# STM32F411xE register map
File version: 1.0
Registers are 32-bit, read-write, reset 0x0 unless marked. A register's access mark holds for its fields unless they carry their own. Offsets are from the block's base; [hi:lo] are bit positions; {n}, {i} and the like mark numbered series.

## PWR — Power Control
Base 0x40007000
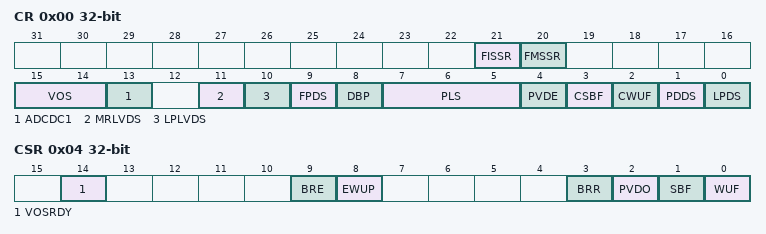
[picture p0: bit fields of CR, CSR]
0x00 CR — PWR power control register
  [21] FISSR — Flash Interface Stop while System Run
  [20] FMSSR — Flash Memory Sleep System Run
  [15:14] VOS — VOS[1:0] bits (Regulator voltage scaling output selection)
    3=SCALE1; 2=SCALE2; 1=SCALE3
  [13] ADCDC1 — Refer to AN4073 on how to use this bit
  [11] MRLVDS — Main Regulator Low Voltage in Deep Sleep mode
  [10] LPLVDS — Low Power Regulator Low Voltage in Deep Sleep mode
  [9] FPDS — Flash power down in Stop mode
  [8] DBP — Disable Backup Domain write protection
  [7:5] PLS — PLS[2:0] bits (PVD Level Selection)
    0=PVDLEVEL_0 (Voltage threshold detected by PVD 2.2 V); 1=PVDLEVEL_1 (Voltage threshold detected by PVD 2.3 V); 2=PVDLEVEL_2 (Voltage threshold detected by PVD 2.4 V); 3=PVDLEVEL_3 (Voltage threshold detected by PVD 2.5 V); 4=PVDLEVEL_4 (Voltage threshold detected by PVD 2.6 V); 5=PVDLEVEL_5 (Voltage threshold detected by PVD 2.7 V); 6=PVDLEVEL_6 (Voltage threshold detected by PVD 2.8 V); 7=PVDLEVEL_7 (Voltage threshold detected by PVD 2.9 V)
  [4] PVDE — Power Voltage Detector Enable
  [3] CSBF — Clear Standby Flag
  [2] CWUF — Clear Wakeup Flag
  [1] PDDS — Power Down Deepsleep
  [0] LPDS — Low-Power Deepsleep
    0=MAIN (Voltage Regulator in main mode during deepsleep mode); 1=LOW_POWER (Voltage Regulator in low-power mode during deepsleep mode)
0x04 CSR — PWR power control/status register
  [14] VOSRDY — Regulator voltage scaling output selection ready
  [9] BRE — Backup regulator enable
  [8] EWUP — Enable WKUP pin
  [3] BRR — Backup regulator ready
  [2] PVDO — PVD Output
  [1] SBF — Standby Flag
  [0] WUF — Wakeup Flag

## SYSCFG — System configuration controller
Base 0x40013800
0x00 MEMRMP — SYSCFG memory remap register
  [1:0] MEM_MODE — SYSCFG_Memory Remap Config
    0=FLASH (Main Flash memory mapped at 0x00000000); 1=SYSTEMFLASH (System Flash memory mapped at 0x00000000); 3=SRAM (SRAM1 mapped at 0x00000000)
0x04 PMC — SYSCFG peripheral mode configuration register
  [16] ADC1DC2 — Refer to AN4073 on how to use this bit
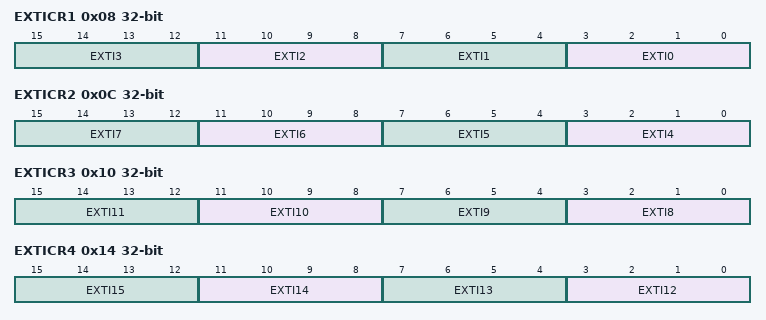
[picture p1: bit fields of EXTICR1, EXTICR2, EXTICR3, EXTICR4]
0x08 EXTICR1 — SYSCFG external interrupt configuration registers
  [4n+3:4n] EXTI{n} (n=0..3) — EXTI {n} configuration
0x0C EXTICR2 — SYSCFG external interrupt configuration registers
  [4n-13:4n-16] EXTI{n} (n=4..7) — EXTI {n} configuration
0x10 EXTICR3 — SYSCFG external interrupt configuration registers
  [4n-29:4n-32] EXTI{n} (n=8..11) — EXTI {n} configuration
0x14 EXTICR4 — SYSCFG external interrupt configuration registers
  [4n-45:4n-48] EXTI{n} (n=12..15) — EXTI {n} configuration
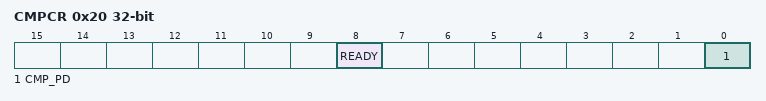
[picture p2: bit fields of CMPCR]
0x20 CMPCR — SYSCFG Compensation cell control register
  [8] READY — Compensation cell power-down
  [0] CMP_PD — Compensation cell ready flag

## EXTI — External Interrupt/Event Controller
Base 0x40013C00
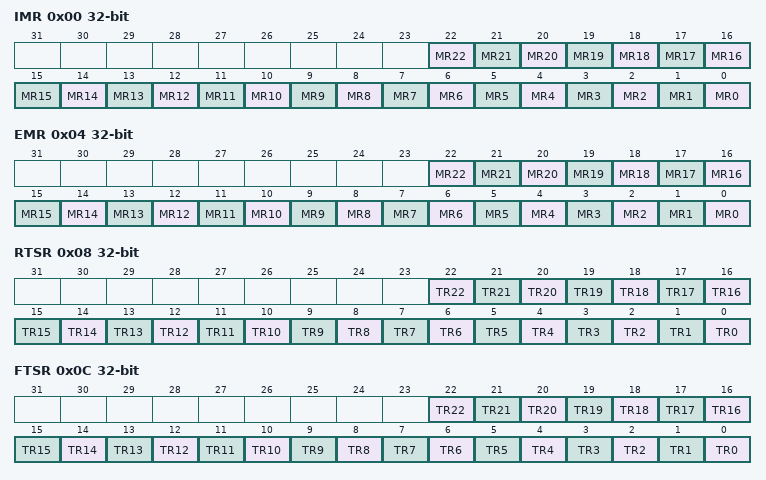
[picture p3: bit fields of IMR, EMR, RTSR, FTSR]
0x00 IMR — EXTI Interrupt mask register
  [n] MR{n} (n=0..22) — Interrupt Mask on line {n}
0x04 EMR — EXTI Event mask register
  [n] MR{n} (n=0..22) — Event Mask on line {n}
0x08 RTSR — EXTI Rising trigger selection register
  [n] TR{n} (n=0..22) — Rising trigger event configuration bit of line {n}
0x0C FTSR — EXTI Falling trigger selection register
  [n] TR{n} (n=0..22) — Falling trigger event configuration bit of line {n}
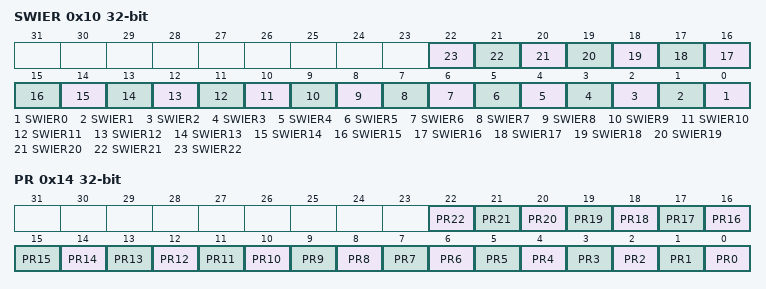
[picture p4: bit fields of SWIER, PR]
0x10 SWIER — EXTI Software interrupt event register
  [n] SWIER{n} (n=0..22) — Software Interrupt on line {n}
0x14 PR — EXTI Pending register
  [n] PR{n} (n=0..22) — Pending bit for line {n}

## TIM10 — TIM
Base 0x40014400
Same registers: TIM11 0x40014800
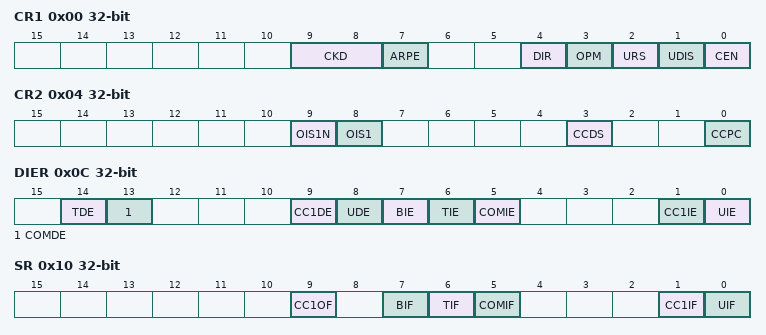
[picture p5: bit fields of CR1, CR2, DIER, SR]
0x00 CR1 — TIM control register 1
  [9:8] CKD — CKD[1:0] bits (clock division)
    0=DIV1 (tDTS=tCK_INT); 1=DIV2 (tDTS=2*tCK_INT); 2=DIV4 (tDTS=4*tCK_INT)
  [7] ARPE — Auto-reload preload enable
  [4] DIR — Direction
    0=UP (Timer counter counts up); 1=DOWN (Timer counter counts down)
  [3] OPM — One pulse mode
    1=SINGLE (Counter stops counting at the next update event); 0=REPETITIVE (Counter is not stopped at update event)
  [2] URS — Update request source
    0=REGULAR (Counter overflow/underflow, Setting the UG bit or Update generation through the slave mode controller generates an update request); 1=COUNTER (Only counter overflow/underflow generates an update request)
  [1] UDIS — Update disable
  [0] CEN — Counter enable
0x04 CR2 — TIM control register 2
  [9] OIS1N — Output Idle state 1 (OC1N output)
  [8] OIS1 — Output Idle state 1 (OC1 output)
  [3] CCDS — Capture/Compare DMA Selection
    0=CC (CCx DMA request sent when CCx event occurs); 1=UPDATE (CCx DMA requests sent when update event occurs)
  [0] CCPC — Capture/Compare Preloaded Control
0x0C DIER — TIM DMA/interrupt enable register
  [14] TDE — Trigger DMA request enable
  [13] COMDE — COM DMA request enable
  [9] CC1DE — Capture/Compare 1 DMA request enable
  [8] UDE — Update DMA request enable
  [7] BIE — Break interrupt enable
  [6] TIE — Trigger interrupt enable
  [5] COMIE — COM interrupt enable
  [1] CC1IE — Capture/Compare 1 interrupt enable
  [0] UIE — Update interrupt enable
0x10 SR — TIM status register
  [9] CC1OF — Capture/Compare 1 Overcapture Flag
  [7] BIF — Break interrupt Flag
  [6] TIF — Trigger interrupt Flag
  [5] COMIF — COM interrupt Flag
  [1] CC1IF — Capture/Compare 1 interrupt Flag
  [0] UIF — Update interrupt Flag
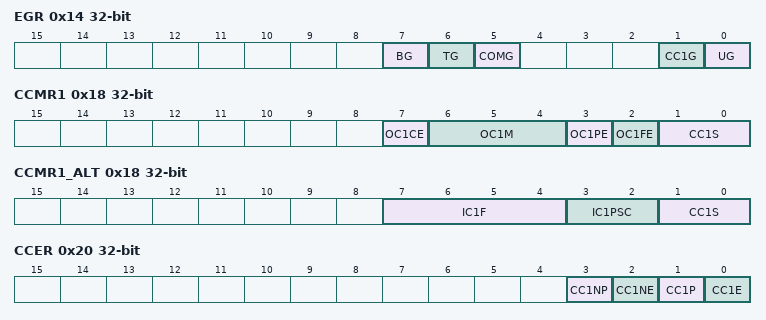
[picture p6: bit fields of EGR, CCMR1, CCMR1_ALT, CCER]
0x14 EGR — TIM event generation register
  [7] BG — Break Generation
  [6] TG — Trigger Generation
  [5] COMG — Capture/Compare Control Update Generation
  [1] CC1G — Capture/Compare 1 Generation
  [0] UG — Update Generation
0x18 CCMR1 — TIM capture/compare mode register 1
  [7] OC1CE — Output Compare 1Clear Enable
  [6:4] OC1M — OC1M[2:0] bits (Output Compare 1 Mode)
  [3] OC1PE — Output Compare 1 Preload enable
  [2] OC1FE — Output Compare 1 Fast enable
  [1:0] CC1S — CC1S[1:0] bits (Capture/Compare 1 Selection)
0x18 CCMR1_ALT (alternate view of CCMR1) — TIM capture/compare mode register 1
  [7:4] IC1F — IC1F[3:0] bits (Input Capture 1 Filter)
  [3:2] IC1PSC — IC1PSC[1:0] bits (Input Capture 1 Prescaler)
  [1:0] CC1S — CC1S[1:0] bits (Capture/Compare 1 Selection)
0x20 CCER — TIM capture/compare enable register
  [3] CC1NP — Capture/Compare 1 Complementary output Polarity
  [2] CC1NE — Capture/Compare 1 Complementary output enable
  [1] CC1P — Capture/Compare 1 output Polarity
  [0] CC1E — Capture/Compare 1 output enable
0x24 CNT — TIM counter register
  [15:0] CNT — Counter Value
0x28 PSC — TIM prescaler
  [15:0] PSC — Prescaler Value
0x2C ARR — TIM auto-reload register
  [15:0] ARR — actual auto-reload Value
0x34 CCR1 — TIM capture/compare register 1
  [15:0] CCR1 — Capture/Compare 1 Value
0x4C DMAR — TIM DMA address for full transfer
  [15:0] DMAB — DMA register for burst accesses
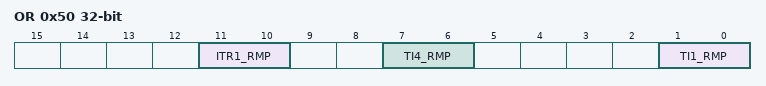
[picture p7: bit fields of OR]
0x50 OR — TIM option register
  [11:10] ITR1_RMP — ITR1_RMP[1:0] bits (TIM2 Internal trigger 1 remap)
  [7:6] TI4_RMP — TI4_RMP[1:0] bits (TIM5 Input 4 remap)
  [1:0] TI1_RMP — TI1_RMP[1:0] bits (TIM11 Input Capture 1 remap)
